# STM32L562 register map
File version: 1.1
Registers are 32-bit, read-write, reset 0x0 unless marked. A register's access mark holds for its fields unless they carry their own. Offsets are from the block's base; [hi:lo] are bit positions; {n}, {i} and the like mark numbered series; 'fields as' and 'values as' point back to an identical list.

## GPIOA — General-purpose I/Os
Base 0x42020000
Same registers: SEC_GPIOA 0x52020000
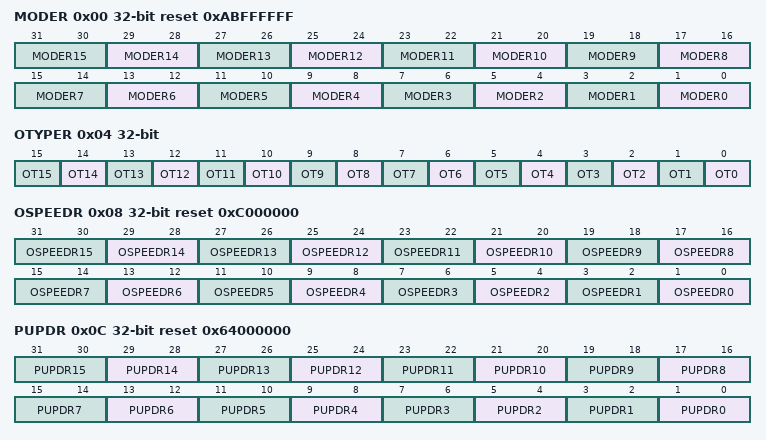
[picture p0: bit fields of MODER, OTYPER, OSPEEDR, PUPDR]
0x00 MODER reset 0xABFFFFFF — GPIO port mode register
  [2n+1:2n] MODER{n} (n=0..15) — Port x configuration bits (y = 0..15)
0x04 OTYPER — GPIO port output type register
  [n] OT{n} (n=0..15) — Port x configuration bits (y = 0..15)
0x08 OSPEEDR reset 0xC000000 — GPIO port output speed register
  [2n+1:2n] OSPEEDR{n} (n=0..15) — Port x configuration bits (y = 0..15)
0x0C PUPDR reset 0x64000000 — GPIO port pull-up/pull-down register
  [2n+1:2n] PUPDR{n} (n=0..15) — Port x configuration bits (y = 0..15)
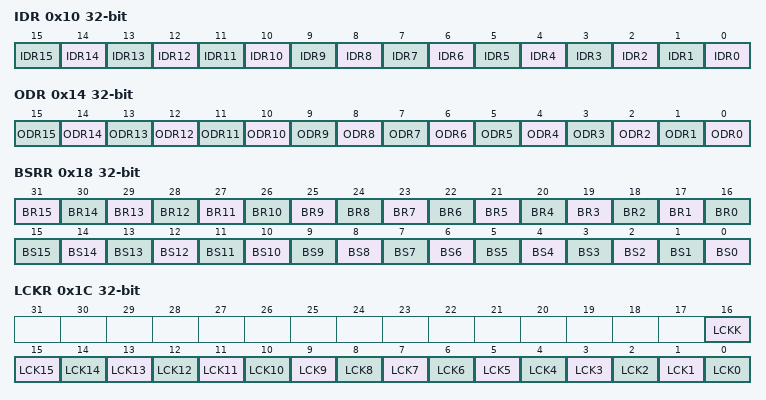
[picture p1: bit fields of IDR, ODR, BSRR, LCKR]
0x10 IDR ro — GPIO port input data register
  [n] IDR{n} (n=0..15) — Port input data (y = 0..15)
0x14 ODR — GPIO port output data register
  [n] ODR{n} (n=0..15) — Port output data (y = 0..15)
0x18 BSRR wo — GPIO port bit set/reset register
  [n+16] BR{n} (n=1..15) — Port x reset bit y (y = 0..15)
  [16] BR0 — Port x set bit y (y= 0..15)
  [n] BS{n} (n=0..15) — Port x set bit y (y= 0..15)
0x1C LCKR — GPIO port configuration lock register
  [16] LCKK — Port x lock bit y (y= 0..15)
  [n] LCK{n} (n=0..15) — Port x lock bit y (y= 0..15)
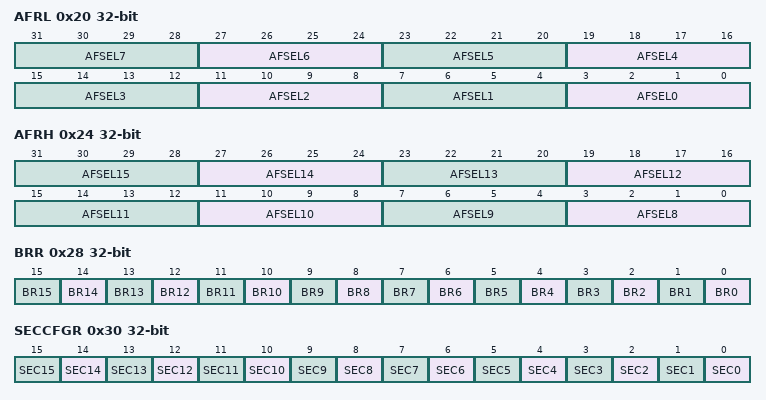
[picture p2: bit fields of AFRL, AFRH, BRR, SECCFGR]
0x20 AFRL — GPIO alternate function low register
  [4n+3:4n] AFSEL{n} (n=0..7) — Alternate function selection for port x bit y (y = 0..7)
0x24 AFRH — GPIO alternate function high register
  [4n-29:4n-32] AFSEL{n} (n=8..15) — Alternate function selection for port x bit y (y = 8..15)
0x28 BRR wo — GPIO port bit reset register
  [n] BR{n} (n=0..15) — Port x reset IO pin y
0x30 SECCFGR wo — GPIO secure configuration register
  [n] SEC{n} (n=0..15) — I/O pin of Port x secure bit enable

## GPIOB — General-purpose I/Os
Base 0x42020400
Same registers: SEC_GPIOB 0x52020400
Registers as GPIOA; these are added or differ:
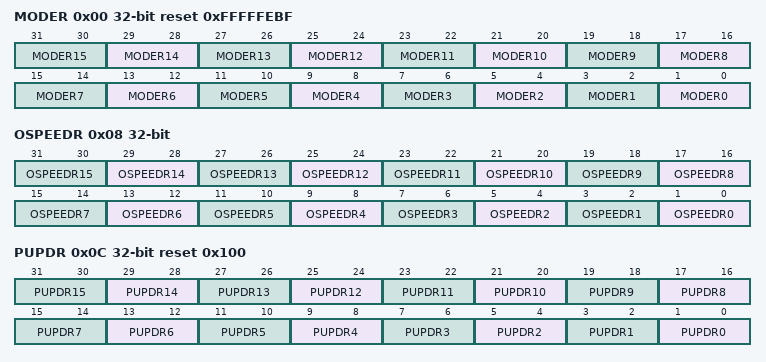
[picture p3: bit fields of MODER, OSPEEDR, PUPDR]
0x00 MODER reset 0xFFFFFEBF — GPIO port mode register
  [2n+1:2n] MODER{n} (n=0..15) — Port x configuration bits (y = 0..15)
0x08 OSPEEDR — GPIO port output speed register
  [2n+1:2n] OSPEEDR{n} (n=0..15) — Port x configuration bits (y = 0..15)
0x0C PUPDR reset 0x100 — GPIO port pull-up/pull-down register
  [2n+1:2n] PUPDR{n} (n=0..15) — Port x configuration bits (y = 0..15)

## GPIOC — General-purpose I/Os
Base 0x42020800
Same registers: GPIOD 0x42020C00, GPIOE 0x42021000, GPIOF 0x42021400, GPIOG 0x42021800, SEC_GPIOC 0x52020800, SEC_GPIOD 0x52020C00, SEC_GPIOE 0x52021000, SEC_GPIOF 0x52021400, SEC_GPIOG 0x52021800
Registers as GPIOB; these are added or differ:
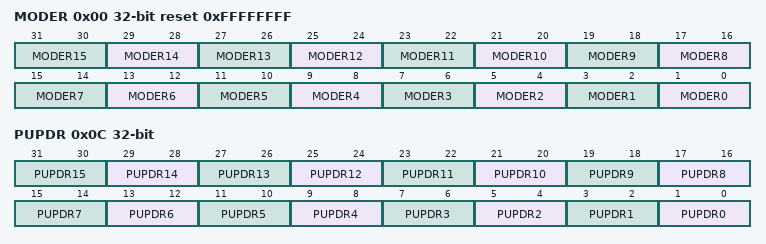
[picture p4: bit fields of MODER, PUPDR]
0x00 MODER reset 0xFFFFFFFF — GPIO port mode register
  [2n+1:2n] MODER{n} (n=0..15) — Port x configuration bits (y = 0..15)
0x0C PUPDR — GPIO port pull-up/pull-down register
  [2n+1:2n] PUPDR{n} (n=0..15) — Port x configuration bits (y = 0..15)

## GPIOH — General-purpose I/Os
Base 0x42021C00
Same registers: SEC_GPIOH 0x52021C00
Registers as GPIOC; these are added or differ:
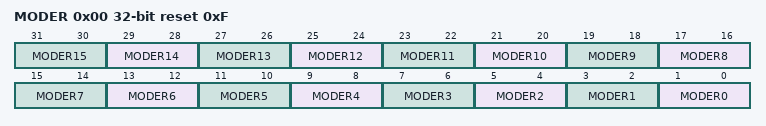
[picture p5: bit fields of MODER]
0x00 MODER reset 0xF — GPIO port mode register
  [2n+1:2n] MODER{n} (n=0..15) — Port x configuration bits (y = 0..15)

## TAMP — Tamper and backup registers
Base 0x40003400
Same registers: SEC_TAMP 0x50003400
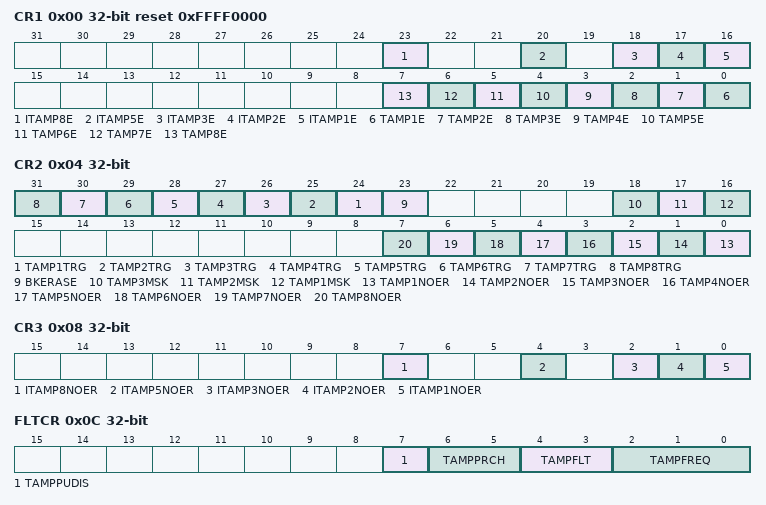
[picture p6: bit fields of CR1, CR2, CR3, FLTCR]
0x00 CR1 reset 0xFFFF0000 — control register 1
  [23] ITAMP8E — ITAMP5E
  [20] ITAMP5E
  [18] ITAMP3E
  [17] ITAMP2E
  [16] ITAMP1E
  [n-1] TAMP{n}E (n=1..8)
0x04 CR2 — control register 2
  [n+23] TAMP{n}TRG (n=1..8), [23] BKERASE, [18] TAMP3MSK, [17] TAMP2MSK, [16] TAMP1MSK, [n-1] TAMP{n}NOER (n=1..8)
0x08 CR3 — control register 3
  [7] ITAMP8NOER, [4] ITAMP5NOER, [2] ITAMP3NOER, [1] ITAMP2NOER, [0] ITAMP1NOER
0x0C FLTCR — TAMP filter control register
  [7] TAMPPUDIS, [6:5] TAMPPRCH, [4:3] TAMPFLT, [2:0] TAMPFREQ
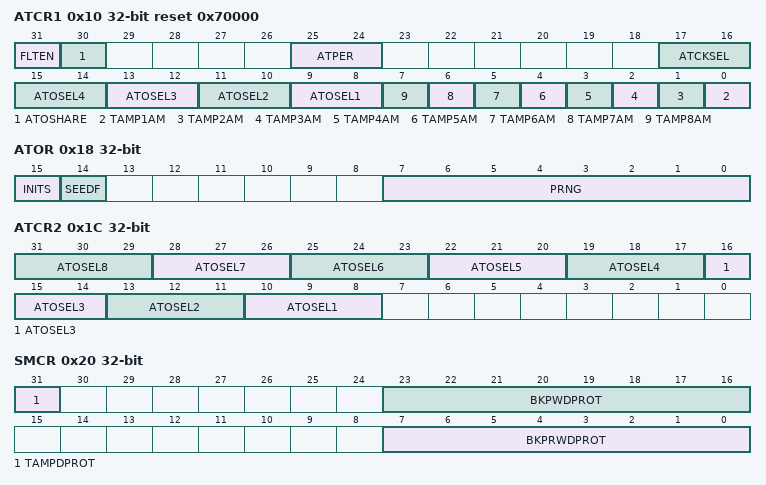
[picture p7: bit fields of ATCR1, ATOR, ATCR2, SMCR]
0x10 ATCR1 reset 0x70000 — TAMP active tamper control register 1
  [31] FLTEN, [30] ATOSHARE, [25:24] ATPER, [17:16] ATCKSEL, [2n+7:2n+6] ATOSEL{n} (n=1..4), [n-1] TAMP{n}AM (n=1..8)
0x14 ATSEEDR wo — TAMP active tamper seed register
  [31:0] SEED — Pseudo-random generator seed value
0x18 ATOR ro — TAMP active tamper output register
  [15] INITS — Active tamper initialization status
  [14] SEEDF — Seed running flag
  [7:0] PRNG — Pseudo-random generator value
0x1C ATCR2 — TAMP active tamper control register 2
  [3n+7:3n+5] ATOSEL{n} (n=1..8)
0x20 SMCR — TAMP secure mode register
  [31] TAMPDPROT — Tamper protection
  [23:16] BKPWDPROT — Backup registers write protection offset
  [7:0] BKPRWDPROT — Backup registers read/write protection offset
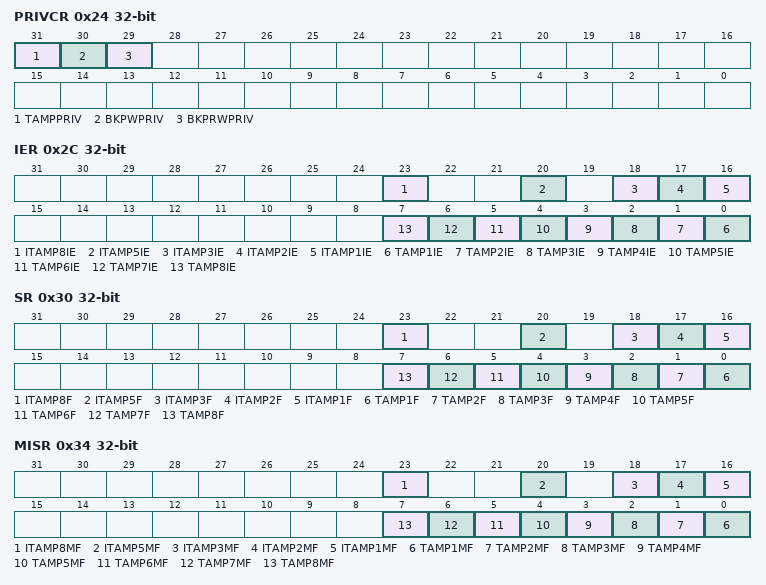
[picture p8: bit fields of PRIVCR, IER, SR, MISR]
0x24 PRIVCR — TAMP privilege mode control register
  [31] TAMPPRIV — Tamper privilege protection
  [30] BKPWPRIV — Backup registers zone 2 privilege protection
  [29] BKPRWPRIV — Backup registers zone 1 privilege protection
0x2C IER — TAMP interrupt enable register
  [23] ITAMP8IE, [20] ITAMP5IE, [18] ITAMP3IE, [17] ITAMP2IE, [16] ITAMP1IE, [n-1] TAMP{n}IE (n=1..8)
0x30 SR ro — TAMP status register
  [23] ITAMP8F, [20] ITAMP5F, [18] ITAMP3F, [17] ITAMP2F, [16] ITAMP1F, [n-1] TAMP{n}F (n=1..8)
0x34 MISR ro — TAMP masked interrupt status register
  [23] ITAMP8MF, [20] ITAMP5MF, [18] ITAMP3MF, [17] ITAMP2MF, [16] ITAMP1MF, [n-1] TAMP{n}MF (n=1..8)
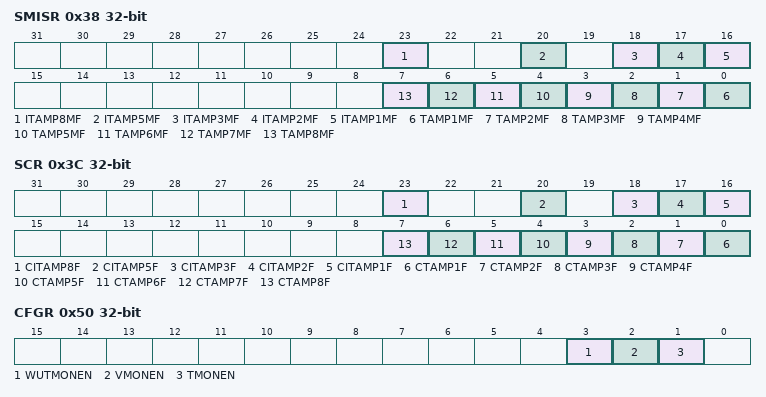
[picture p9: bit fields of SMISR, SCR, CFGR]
0x38 SMISR ro — TAMP secure masked interrupt status register
  fields as MISR
0x3C SCR wo — TAMP status clear register
  [23] CITAMP8F, [20] CITAMP5F, [18] CITAMP3F, [17] CITAMP2F, [16] CITAMP1F, [n-1] CTAMP{n}F (n=1..8)
0x40 COUNTR ro — TAMP monotonic counter register
  [31:0] COUNT
0x50 CFGR — TAMP configuration register
  [3] WUTMONEN, [2] VMONEN, [1] TMONEN
{0x100+4i} BKP{i}R (i=0..31) — TAMP backup register
  [31:0] BKP
